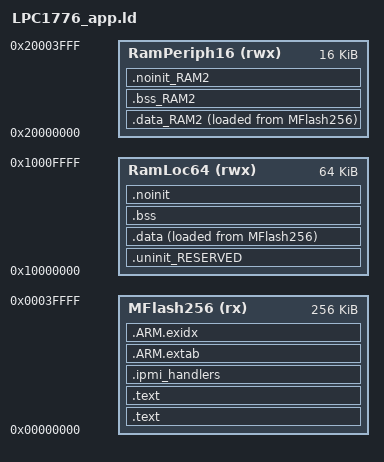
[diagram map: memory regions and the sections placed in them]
MEMORY
{
  /* Define each memory region */
  MFlash256 (rx) : ORIGIN = 0x0, LENGTH = 0x40000 /* 256K bytes (alias Flash) */  
  RamLoc64 (rwx) : ORIGIN = 0x10000000, LENGTH = 0x10000 /* 64K bytes (alias RAM) */  
  RamPeriph16 (rwx) : ORIGIN = 0x20000000, LENGTH = 0x4000 /* 16K bytes (alias RAM2) */  
}

  /* Define a symbol for the top of each memory region */
  __base_MFlash256 = 0x0  ; /* MFlash256 */  
  __base_Flash = 0x0 ; /* Flash */  
  __top_MFlash256 = 0x0 + 0x40000 ; /* 256K bytes */  
  __top_Flash = 0x0 + 0x40000 ; /* 256K bytes */  
  __base_RamLoc64 = 0x10000000  ; /* RamLoc64 */  
  __base_RAM = 0x10000000 ; /* RAM */  
  __top_RamLoc64 = 0x10000000 + 0x10000 ; /* 64K bytes */  
  __top_RAM = 0x10000000 + 0x10000 ; /* 64K bytes */  
  __base_RamPeriph16 = 0x20000000  ; /* RamPeriph16 */  
  __base_RAM2 = 0x20000000 ; /* RAM2 */  
  __top_RamPeriph16 = 0x20000000 + 0x4000 ; /* 16K bytes */  
  __top_RAM2 = 0x20000000 + 0x4000 ; /* 16K bytes */  

ENTRY(ResetISR)
EXTERN(NMI_Handler)
EXTERN(HardFault_Handler)
EXTERN(MemManage_Handler)
EXTERN(BusFault_Handler)
EXTERN(UsageFault_Handler)

SECTIONS
{
    /* MAIN TEXT SECTION */
    .text : ALIGN(4)
    {
        FILL(0xff)
        __vectors_start__ = ABSOLUTE(.) ;
        KEEP(*(.isr_vector))
        /* Global Section Table */
        . = ALIGN(4) ; 
        __section_table_start = .;
        __data_section_table = .;
        LONG(LOADADDR(.data));
        LONG(    ADDR(.data));
        LONG(  SIZEOF(.data));
        LONG(LOADADDR(.data_RAM2));
        LONG(    ADDR(.data_RAM2));
        LONG(  SIZEOF(.data_RAM2));
        __data_section_table_end = .;
        __bss_section_table = .;
        LONG(    ADDR(.bss));
        LONG(  SIZEOF(.bss));
        LONG(    ADDR(.bss_RAM2));
        LONG(  SIZEOF(.bss_RAM2));
        __bss_section_table_end = .;
        __section_table_end = . ;
	    /* End of Global Section Table */

        *(.after_vectors*)

    } >MFlash256

    .text : ALIGN(4)    
    {
        *(.text*)
        *(.rodata .rodata.* .constdata .constdata.*)
        . = ALIGN(4);
    } > MFlash256
    
	.ipmi_handlers : ALIGN(4)
	{
	      _ipmi_handlers = .;
	      KEEP(*(.ipmi_handlers))
	      _eipmi_handlers = .;
	} > MFlash256
    
    /*
     * for exception handling/unwind - some Newlib functions (in common
     * with C++ and STDC++) use this. 
     */
    .ARM.extab : ALIGN(4) 
    {
        *(.ARM.extab* .gnu.linkonce.armextab.*)
    } > MFlash256
    __exidx_start = .;

    .ARM.exidx : ALIGN(4)
    {
        *(.ARM.exidx* .gnu.linkonce.armexidx.*)
    } > MFlash256
    __exidx_end = .;

    _etext = .;
        
    /* DATA section for RamPeriph16 */
    .data_RAM2 : ALIGN(4)
    {
        FILL(0xff)
        PROVIDE(__start_data_RAM2 = .) ;
        *(.ramfunc.$RAM2)
        *(.ramfunc.$RamPeriph16)
        *(.data.$RAM2*)
        *(.data.$RamPeriph16*)
        . = ALIGN(4) ;
        PROVIDE(__end_data_RAM2 = .) ;
     } > RamPeriph16 AT>MFlash256

    /* MAIN DATA SECTION */
    .uninit_RESERVED : ALIGN(4)
    {
        KEEP(*(.bss.$RESERVED*))
        . = ALIGN(4) ;
        _end_uninit_RESERVED = .;
    } > RamLoc64
    /* Main DATA section (RamLoc64) */
    .data : ALIGN(4)
    {
       FILL(0xff)
       _data = . ;
       *(vtable)
       *(.ramfunc*)
       *(.data*)
       . = ALIGN(4) ;
       _edata = . ;
    } > RamLoc64 AT>MFlash256
    /* BSS section for RamPeriph16 */
    .bss_RAM2 : ALIGN(4)
    {
       PROVIDE(__start_bss_RAM2 = .) ;
       *(.bss.$RAM2*)
       *(.bss.$RamPeriph16*)
       . = ALIGN (. != 0 ? 4 : 1) ; /* avoid empty segment */
       PROVIDE(__end_bss_RAM2 = .) ;
    } > RamPeriph16 
    /* MAIN BSS SECTION */
    .bss : ALIGN(4)
    {
        _bss = .;
        *(.bss*)
        *(COMMON)
        . = ALIGN(4) ;
        _ebss = .;
        PROVIDE(end = .);
    } > RamLoc64
    /* NOINIT section for RamPeriph16 */
    .noinit_RAM2 (NOLOAD) : ALIGN(4)
    {
       *(.noinit.$RAM2*)
       *(.noinit.$RamPeriph16*)
       . = ALIGN(4) ;
    } > RamPeriph16 
    /* DEFAULT NOINIT SECTION */
    .noinit (NOLOAD): ALIGN(4)
    {
        _noinit = .;
        *(.noinit*) 
         . = ALIGN(4) ;
        _end_noinit = .;
    } > RamLoc64

    PROVIDE(_pvHeapStart = DEFINED(__user_heap_base) ? __user_heap_base : .);
    PROVIDE(_vStackTop = DEFINED(__user_stack_top) ? __user_stack_top : __top_RamLoc64 - 0);

    /* ## Create checksum value (used in startup) ## */
    PROVIDE(__valid_user_code_checksum = 0 - 
                                         (_vStackTop 
                                         + (ResetISR + 1) 
                                         + (NMI_Handler + 1) 
                                         + (HardFault_Handler + 1) 
                                         + (( DEFINED(MemManage_Handler) ? MemManage_Handler : 0 ) + 1)   /* MemManage_Handler may not be defined */
                                         + (( DEFINED(BusFault_Handler) ? BusFault_Handler : 0 ) + 1)     /* BusFault_Handler may not be defined */
                                         + (( DEFINED(UsageFault_Handler) ? UsageFault_Handler : 0 ) + 1) /* UsageFault_Handler may not be defined */
                                         ) );
    PROVIDE(_VectorChecksum = 0 - (_vStackTop + ResetISR + NMI_Handler + HardFault_Handler + MemManage_Handler + BusFault_Handler + UsageFault_Handler + 6 ));
}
